# MSPM0G150X register map
Vendor: Texas Instruments; File version: This preliminary header file does not have a version number - build date: 2023-02-21 16:25:48
CPU: CM0 r0p1, little endian, MPU, no FPU, 3 interrupt priority bits
Registers are 32-bit, read-write, reset 0x0 unless marked. A register's access mark holds for its fields unless they carry their own. Offsets are from the block's base; [hi:lo] are bit positions; {n}, {i} and the like mark numbered series.

## MATHACL — PERIPHERALREGION
Base 0x40410000
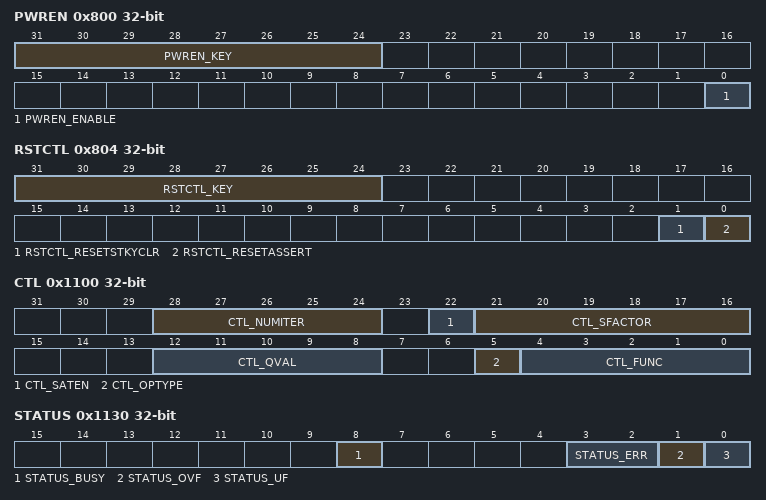
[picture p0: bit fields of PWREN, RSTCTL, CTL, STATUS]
0x800 PWREN — Power enable
  [31:24] PWREN_KEY wo — KEY to allow Power State Change
    38=PWREN_KEY_UNLOCK_W (_TO_UNLOCK_W_)
  [0] PWREN_ENABLE — Enable the power
    0=PWREN_ENABLE_DISABLE (DISABLE); 1=PWREN_ENABLE_ENABLE (ENABLE)
0x804 RSTCTL wo — Reset Control
  [31:24] RSTCTL_KEY — Unlock key
    177=RSTCTL_KEY_UNLOCK_W (_TO_UNLOCK_W_)
  [1] RSTCTL_RESETSTKYCLR — Clear the RESETSTKY bit in the STAT register
    0=RSTCTL_RESETSTKYCLR_NOP (NOP); 1=RSTCTL_RESETSTKYCLR_CLR (CLR)
  [0] RSTCTL_RESETASSERT — Assert reset to the peripheral
    0=RSTCTL_RESETASSERT_NOP (NOP); 1=RSTCTL_RESETASSERT_ASSERT (ASSERT)
0x814 STAT ro — Status Register
  [16] STAT_RESETSTKY — This bit indicates, if the peripheral was reset, since this bit was cleared by RESETSTKYCLR in the RSTCTL register
    0=STAT_RESETSTKY_NORES (NORES); 1=STAT_RESETSTKY_RESET (RESET)
0x1100 CTL — Control Register
  [28:24] CTL_NUMITER — Number of iterations, applicable if the function does the computations iteratively, for example sine/cosine/atan2/sqrt. Note: A value of 0 is interpreted as 31.
  [22] CTL_SATEN — Saturation enable This bit is shared among DIV, SQUARE32, MPY32, MAC and SAC functions. When enabled, it will make the result to saturate to maximum value in case of an overflow event When disabled, the result will overflow to an unknown value.
    0=CTL_SATEN_DISABLE (DISABLE); 1=CTL_SATEN_ENABLE (ENABLE)
  [21:16] CTL_SFACTOR — Scaling factor. In case of SQRT function, the input operand needs to be in a range. If not it has to be scaled to 2^(+/-n). This field should be written with the value 'n'.
  [12:8] CTL_QVAL — Indicates the fractional bits in the operands, ranges from 0 to 31. Applicable to DIV function.
    {v}=CTL_QVAL_Q{v} (Q{v}) (v=0..31)
  [5] CTL_OPTYPE — Operand type, could signed or unsigned. applicable to DIV function.
    0=CTL_OPTYPE_UNSIGNED (UNSIGNED); 1=CTL_OPTYPE_SIGNED (SIGNED)
  [4:0] CTL_FUNC — ULP_ADCHP Enable Conversions.
    0=CTL_FUNC_NOP (NOP); 1=CTL_FUNC_SINCOS (SINCOS); 2=CTL_FUNC_ATAN2 (ATAN2); 4=CTL_FUNC_DIV (DIV); 5=CTL_FUNC_SQRT (SQRT); 6=CTL_FUNC_MPY32 (MPY32); 7=CTL_FUNC_SQUARE32 (SQUARE32); 8=CTL_FUNC_MPY64 (MPY64); 9=CTL_FUNC_SQUARE64 (SQUARE64); 10=CTL_FUNC_MAC (MAC); 11=CTL_FUNC_SAC (SAC)
0x1118 OP2 — Operand 2 register.
  [31:0] OP2_DATA — Operand 2 Register
0x111C OP1 — Operand 1 register.
  [31:0] OP1_DATA
0x1120 RES1 — Result 1 register.
  [31:0] RES1_DATA — Result 1 register
0x1124 RES2 — Result 2 register.
  [31:0] RES2_DATA — Result 2 register
0x1130 STATUS ro
  [8] STATUS_BUSY — MATHACL busy bit.
    0=STATUS_BUSY_DONE (DONE); 1=STATUS_BUSY_NOTDONE (NOTDONE)
  [3:2] STATUS_ERR — Incorrect inputs/outputs.
    0=STATUS_ERR_NOERROR (NOERROR); 1=STATUS_ERR_DIVBY0 (DIVBY0)
  [1] STATUS_OVF — Overflow bit for MPY32, SQUARE32, DIV, MAC, and SAC functions This bit will be set on overflow and will retain its value until cleared by writing 1 into CLR.CLR_OVF
  [0] STATUS_UF — Underflow Flag
    0=STATUS_UF_NO_UNDERFLOW (NO_UNDERFLOW); 1=STATUS_UF_UNDERFLOW (UNDERFLOW)
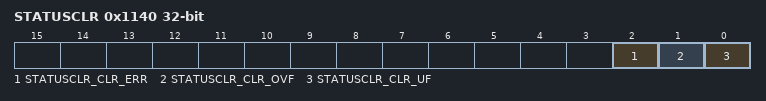
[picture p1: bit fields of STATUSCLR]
0x1140 STATUSCLR wo — Status flag clear register
  [2] STATUSCLR_CLR_ERR — Write 1 to this bit to clear STATUS.ERR field
    0=STATUSCLR_CLR_ERR_NO_EFFECT (NO_EFFECT); 1=STATUSCLR_CLR_ERR_CLR (CLR)
  [1] STATUSCLR_CLR_OVF — Write 1 to this bit to clear STATUS.OVF bit
    0=STATUSCLR_CLR_OVF_NO_EFFECT (NO_EFFECT); 1=STATUSCLR_CLR_OVF_CLR (CLR)
  [0] STATUSCLR_CLR_UF — Write 1 to this bit to clear STATUS.UF bit
    0=STATUSCLR_CLR_UF_NO_EFFECT (NO_EFFECT); 1=STATUSCLR_CLR_UF_CLR (CLR)
